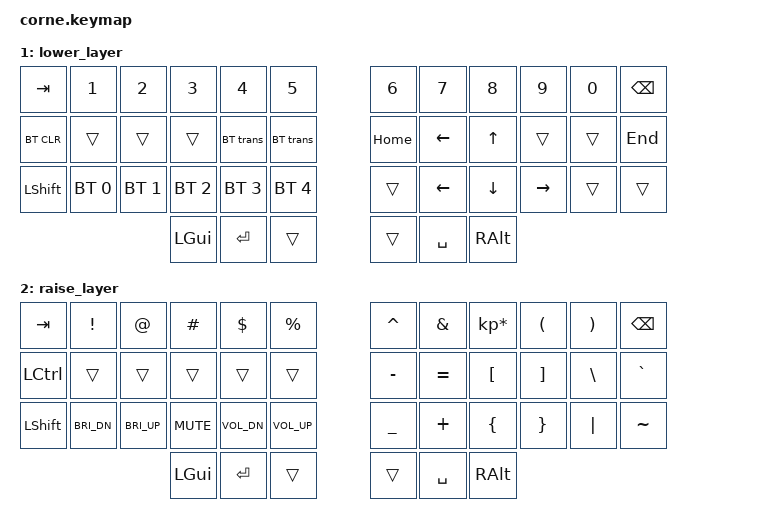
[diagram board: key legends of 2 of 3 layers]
/*
 * Copyright (c) 2020 The ZMK Contributors
 *
 * SPDX-License-Identifier: MIT
 */

#include <behaviors.dtsi>
#include <dt-bindings/zmk/keys.h>
#include <dt-bindings/zmk/bt.h>

/ {
        keymap {
                compatible = "zmk,keymap";

                default_layer {
// -----------------------------------------------------------------------------------------
// |  TAB |  Q  |  W  |  E  |  R  |  T  |   |  Y  |  U   |  I  |  O  |  P  | BKSP |
// | CTRL |  A  |  S  |  D  |  F  |  G  |   |  H  |  J   |  K  |  L  |  ;  |  '   |
// | SHFT |  Z  |  X  |  C  |  V  |  B  |   |  N  |  M   |  ,  |  .  |  /  | ESC  |
//                    | GUI | ENT | LWR |   | RSE | SPC  | ALT |
                        bindings = <
   &kp TAB   &kp Q &kp W &kp E &kp R &kp T   &kp Y &kp U  &kp I     &kp O   &kp P    &kp BSPC
   &kp LCTRL &kp A &kp S &kp D &kp F &kp G   &kp H &kp J  &kp K     &kp L   &kp SEMI &kp SQT
   &kp LSHFT &kp Z &kp X &kp C &kp V &kp B   &kp N &kp M  &kp COMMA &kp DOT &kp FSLH &kp ESC
                     kp LGUI &kp RET &mo 1   &mo 2 &kp SPACE &kp RALT
                        >;
                };
                lower_layer {
// -----------------------------------------------------------------------------------------
// |  TAB |  1  |  2  |  3  |  4  |  5  |   |  6   |  7  |  8  |  9  |  0  | BKSP |
// | BTCLR|     |     |     |     |     |   | HOME |     |  UP |     |     | END  |
// | SHFT | BT1 | BT2 | BT3 | BT4 | BT5 |   |      | LFT | DWN | RGT |     |      |
//                    | GUI | SPC |     |   |      | ENT | ALT |
                        bindings = <
   &kp TAB    &kp N1       &kp N2       &kp N3       &kp N4       &kp N5         &kp N6   &kp N7    &kp N8    &kp N9     &kp N0  &kp BSPC
   &bt BT_CLR &trans       &trans       &trans       &bt trans    &bt trans      &kp HOME &kp LEFT  &kp UP    &trans     &trans  &kp END
   &kp LSHFT  &bt BT_SEL 0 &bt BT_SEL 1 &bt BT_SEL 2 &bt BT_SEL 3 &bt BT_SEL 4   &trans   &kp LEFT  &kp DOWN  &kp RIGHT  &trans  &trans
                                            &kp LGUI      &kp RET       &trans   &trans   &kp SPACE  &kp RALT
                        >;
                };

                raise_layer {
// -----------------------------------------------------------------------------------------
// |  TAB |  !  |  @  |  #   |  $   |  %   |   |  ^  |  &  |  *  |  (  |  )  | BKSP |
// | CTRL |     |     |      |      |      |   |  -  |  =  |  [  |  ]  |  \  |  `   | 
// | SHFT | BR+ | BR- | VOLx | VOL- | VOL+ |   |  _  |  +  |  {  |  }  | "|" |  ~   |
//                    | GUI  | ENT  |      |   |     | SPC | ALT |
                        bindings = <
   &kp  TAB  &kp EXCL      &kp AT        &kp HASH    &kp DLLR      &kp PRCNT      &kp CARET &kp AMPS  &kp KP_MULTIPLY &kp LPAR &kp RPAR &kp BSPC
   &kp LCTRL &trans        &trans        &trans      &trans        &trans         &kp MINUS &kp EQUAL &kp LBKT        &kp RBKT &kp BSLH &kp GRAVE
   &kp LSHFT &kp C_BRI_DN  &kp C_BRI_UP  &kp C_MUTE  &kp C_VOL_DN  &kp C_VOL_UP   &kp UNDER &kp PLUS  &kp LBRC        &kp RBRC &kp PIPE &kp TILDE
                      &kp LGUI      &kp RET       &trans   &trans   &kp SPACE  &kp RALT
                        >;
                };
        };
};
